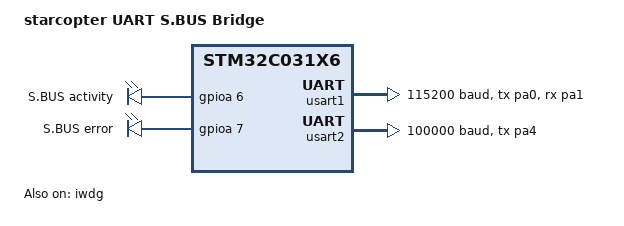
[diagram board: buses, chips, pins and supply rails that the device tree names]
/*
 * SPDX-License-Identifier: MIT
 */

/dts-v1/;
#include <st/c0/stm32c031X6.dtsi>
#include <st/c0/stm32c031f(4-6)px-pinctrl.dtsi>
#include <zephyr/dt-bindings/gpio/gpio.h>

/ {
	model = "starcopter UART S.BUS Bridge";
	compatible = "starcopter,sbus-bridge";

	chosen {
		zephyr,sram = &sram0;
		zephyr,flash = &flash0;
	};

	leds {
		compatible = "gpio-leds";

		led_green: led_0 {
			gpios = <&gpioa 6 GPIO_ACTIVE_HIGH>;
			label = "S.BUS activity";
		};

		led_red: led_1 {
			gpios = <&gpioa 7 GPIO_ACTIVE_HIGH>;
			label = "S.BUS error";
		};
	};

	aliases {
		uart-in = &usart1;
		sbus-out = &usart2;
		led0 = &led_green;
		led1 = &led_red;
		watchdog0 = &iwdg;
	};
};

&clk_hsi {
	status = "okay";
};

&rcc {
	clocks = <&clk_hsi>;
	clock-frequency = <DT_FREQ_M(48)>;
	ahb-prescaler = <1>;
	apb1-prescaler = <1>;
};

/*
 * USART1 IRQ 27 and USART2 IRQ 28 share NVIC priority 0, so RX cannot starve
 * TX mid-byte (and vice versa). Equal priorities are asserted by the application.
 */
&usart1 {
	pinctrl-0 = <&usart1_tx_pa0 &usart1_rx_pa1>;
	pinctrl-names = "default";
	current-speed = <115200>;
	fifo-enable;
	interrupts = <27 0>;
	status = "okay";
};

&usart1_rx_pa1 {
	bias-pull-up;
};

/* USART2 TX-only inverted S.BUS on PA4. */
&usart2 {
	pinctrl-0 = <&usart2_tx_pa4>;
	pinctrl-names = "default";
	current-speed = <100000>;
	parity = "even";
	stop-bits = "2";
	tx-invert;
	fifo-enable;
	interrupts = <28 0>;
	status = "okay";
};

&iwdg {
	status = "okay";
};
